# VPAC0_COMMON_0_IVPAC_TOP_0_CFG_SLV_PAR_VPAC_VISS0_S_VBUSP_VISS_PCID_S_VBUSP_IR_REMAPLUT_LUT_CFG_IRREMAP_LUT register map
Vendor: Texas Instruments
Peripheral module from a debugger description file (folder am62A).
Registers are 32-bit, read-write, reset 0x0 unless marked. A register's access mark holds for its fields unless they carry their own. Offsets are as the file gives them; lines under a group give offsets from that group; [hi:lo] are bit positions; {n}, {i} and the like mark numbered series; 'fields as' and 'values as' point back to an identical list; <NAME> marks a mode.

## VPAC0_COMMON_0_IVPAC_TOP_0_CFG_SLV_PAR_VPAC_VISS0_S_VBUSP_VISS_PCID_S_VBUSP_IR_REMAPLUT_LUT_CFG_IRREMAP_LUT
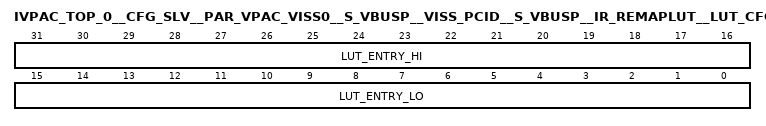
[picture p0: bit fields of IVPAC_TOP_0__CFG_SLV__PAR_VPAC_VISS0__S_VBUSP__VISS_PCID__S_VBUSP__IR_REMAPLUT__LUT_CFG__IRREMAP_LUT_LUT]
0x00 IVPAC_TOP_0__CFG_SLV__PAR_VPAC_VISS0__S_VBUSP__VISS_PCID__S_VBUSP__IR_REMAPLUT__LUT_CFG__IRREMAP_LUT_LUT — Only full 32-bit access it allowed
  [31:16] LUT_ENTRY_HI — The upper LUT entry n+1.
  [15:0] LUT_ENTRY_LO — The lower LUT entry n+0.
